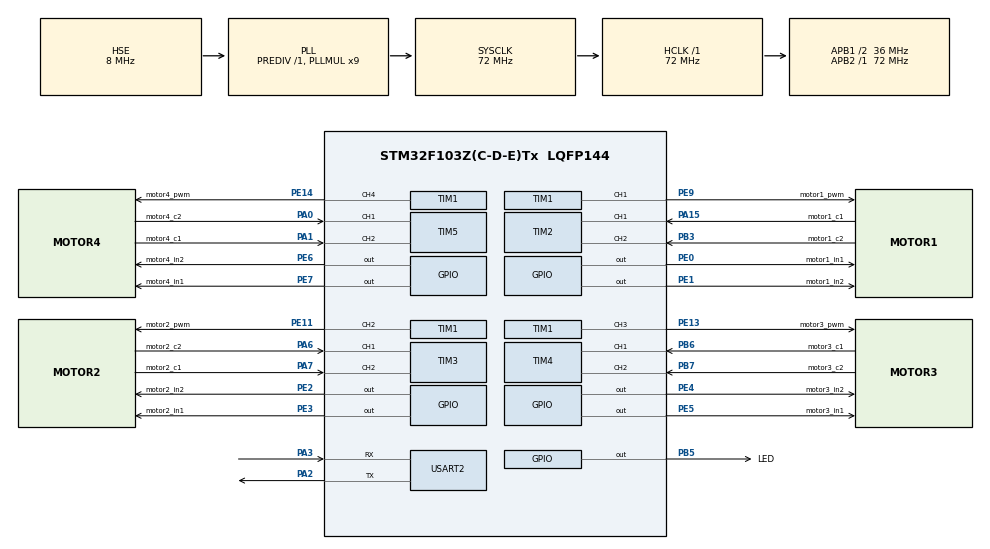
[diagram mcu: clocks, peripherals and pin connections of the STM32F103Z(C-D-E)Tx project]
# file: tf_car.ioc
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Mcu.Family=STM32F1
Mcu.Name=STM32F103Z(C-D-E)Tx
Mcu.Package=LQFP144
NVIC.PriorityGroup=NVIC_PRIORITYGROUP_4
NVIC.TIM2_IRQn=true\:0\:0\:false\:false\:true\:true\:true\:true
NVIC.TIM3_IRQn=true\:0\:0\:false\:false\:true\:true\:true\:true
NVIC.TIM4_IRQn=true\:0\:0\:false\:false\:true\:true\:true\:true
NVIC.TIM5_IRQn=true\:0\:0\:false\:false\:true\:true\:true\:true
NVIC.TIM8_UP_IRQn=true\:0\:0\:false\:false\:true\:true\:true\:true
OSC_IN.Mode=HSE-External-Oscillator
OSC_IN.Signal=RCC_OSC_IN
OSC_OUT.Mode=HSE-External-Oscillator
OSC_OUT.Signal=RCC_OSC_OUT
PA0-WKUP.GPIO_Label=motor4_c2
PA0-WKUP.GPIO_PuPd=GPIO_PULLUP
PA0-WKUP.Signal=S_TIM5_CH1
PA1.GPIO_Label=motor4_c1
PA1.GPIO_PuPd=GPIO_PULLUP
PA1.Signal=S_TIM5_CH2
PA13.Mode=Serial_Wire
PA13.Signal=SYS_JTMS-SWDIO
PA14.Mode=Serial_Wire
PA14.Signal=SYS_JTCK-SWCLK
PA15.GPIO_Label=motor1_c1
PA15.GPIO_PuPd=GPIO_PULLUP
PA15.Signal=S_TIM2_CH1_ETR
PA2.Mode=Asynchronous
PA2.Signal=USART2_TX
PA3.Mode=Asynchronous
PA3.Signal=USART2_RX
PA6.GPIO_Label=motor2_c2
PA6.GPIO_PuPd=GPIO_PULLUP
PA6.Signal=S_TIM3_CH1
PA7.GPIO_Label=motor2_c1
PA7.GPIO_PuPd=GPIO_PULLUP
PA7.Signal=S_TIM3_CH2
PB3.GPIO_Label=motor1_c2
PB3.GPIO_PuPd=GPIO_PULLUP
PB3.Signal=S_TIM2_CH2
PB5.GPIO_Label=LED
PB5.Signal=GPIO_Output
PB6.GPIO_Label=motor3_c1
PB6.GPIO_PuPd=GPIO_PULLUP
PB6.Signal=S_TIM4_CH1
PB7.GPIO_Label=motor3_c2
PB7.GPIO_PuPd=GPIO_PULLUP
PB7.Signal=S_TIM4_CH2
PE0.GPIO_Label=motor1_in1
PE0.Signal=GPIO_Output
PE1.GPIO_Label=motor1_in2
PE1.Signal=GPIO_Output
PE11.GPIO_Label=motor2_pwm
PE11.Signal=S_TIM1_CH2
PE13.GPIO_Label=motor3_pwm
PE13.Signal=S_TIM1_CH3
PE14.GPIO_Label=motor4_pwm
PE14.Signal=S_TIM1_CH4
PE2.GPIO_Label=motor2_in2
PE2.Signal=GPIO_Output
PE3.GPIO_Label=motor2_in1
PE3.Signal=GPIO_Output
PE4.GPIO_Label=motor3_in2
PE4.Signal=GPIO_Output
PE5.GPIO_Label=motor3_in1
PE5.Signal=GPIO_Output
PE6.GPIO_Label=motor4_in2
PE6.Signal=GPIO_Output
PE7.GPIO_Label=motor4_in1
PE7.Signal=GPIO_Output
PE9.GPIO_Label=motor1_pwm
PE9.Signal=S_TIM1_CH1
ProjectManager.HeapSize=0x200
ProjectManager.StackSize=0x400
ProjectManager.TargetToolchain=MDK-ARM V5.32
RCC.AHBFreq_Value=72000000
RCC.APB1CLKDivider=RCC_HCLK_DIV2
RCC.APB1Freq_Value=36000000
RCC.APB1TimFreq_Value=72000000
RCC.APB2Freq_Value=72000000
RCC.APB2TimFreq_Value=72000000
RCC.HCLKFreq_Value=72000000
RCC.PLLMUL=RCC_PLL_MUL9
RCC.PLLSourceVirtual=RCC_PLLSOURCE_HSE
RCC.SYSCLKFreq_VALUE=72000000
RCC.SYSCLKSource=RCC_SYSCLKSOURCE_PLLCLK
RCC.USBFreq_Value=72000000
SH.S_TIM1_CH1.0=TIM1_CH1,PWM Generation1 CH1
SH.S_TIM1_CH2.0=TIM1_CH2,PWM Generation2 CH2
SH.S_TIM1_CH3.0=TIM1_CH3,PWM Generation3 CH3
SH.S_TIM1_CH4.0=TIM1_CH4,PWM Generation4 CH4
SH.S_TIM2_CH1_ETR.0=TIM2_CH1,Encoder_Interface
SH.S_TIM2_CH2.0=TIM2_CH2,Encoder_Interface
SH.S_TIM3_CH1.0=TIM3_CH1,Encoder_Interface
SH.S_TIM3_CH2.0=TIM3_CH2,Encoder_Interface
SH.S_TIM4_CH1.0=TIM4_CH1,Encoder_Interface
SH.S_TIM4_CH2.0=TIM4_CH2,Encoder_Interface
SH.S_TIM5_CH1.0=TIM5_CH1,Encoder_Interface
SH.S_TIM5_CH2.0=TIM5_CH2,Encoder_Interface
TIM1.AutoReloadPreload=TIM_AUTORELOAD_PRELOAD_ENABLE
TIM1.Channel-PWM\ Generation1\ CH1=TIM_CHANNEL_1
TIM1.Channel-PWM\ Generation2\ CH2=TIM_CHANNEL_2
TIM1.Channel-PWM\ Generation3\ CH3=TIM_CHANNEL_3
TIM1.Channel-PWM\ Generation4\ CH4=TIM_CHANNEL_4
TIM1.Period=100-1
TIM1.Prescaler=1440-1
TIM1.Pulse-PWM\ Generation1\ CH1=50
TIM1.Pulse-PWM\ Generation2\ CH2=50
TIM1.Pulse-PWM\ Generation3\ CH3=50
TIM1.Pulse-PWM\ Generation4\ CH4=50
TIM2.EncoderMode=TIM_ENCODERMODE_TI12
TIM2.IC1Filter=6
TIM2.IC2Filter=6
TIM3.EncoderMode=TIM_ENCODERMODE_TI12
TIM3.IC1Filter=6
TIM3.IC2Filter=6
TIM4.EncoderMode=TIM_ENCODERMODE_TI12
TIM4.IC1Filter=6
TIM4.IC2Filter=6
TIM5.EncoderMode=TIM_ENCODERMODE_TI12
TIM5.IC1Filter=6
TIM5.IC2Filter=6
TIM8.AutoReloadPreload=TIM_AUTORELOAD_PRELOAD_ENABLE
TIM8.Period=100-1
TIM8.Prescaler=1440-1
USART2.VirtualMode=VM_ASYNC
VP_TIM8_VS_ClockSourceINT.Mode=Internal
board=custom

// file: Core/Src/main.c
/* USER CODE BEGIN Header */
/**
  ******************************************************************************
  * @file           : main.c
  * @brief          : Main program body
  ******************************************************************************
  * @attention
  *
  * Copyright (c) 2023 STMicroelectronics.
  * All rights reserved.
  *
  * This software is licensed under terms that can be found in the LICENSE file
  * in the root directory of this software component.
  * If no LICENSE file comes with this software, it is provided AS-IS.
  *
  ******************************************************************************
  */
/* USER CODE END Header */
#include "main.h"
#include "tim.h"
#include "usart.h"
#include "gpio.h"

/* USER CODE BEGIN Includes */
#include "stdio.h"
#include "motor.h"
#include "encoder.h"
#include "pid.h"
/* USER CODE END Includes */

void SystemClock_Config(void);

/* USER CODE BEGIN 0 */
extern short encoder1count;
extern short encoder2count;
extern short encoder3count;
extern short encoder4count;
extern tpid pid1,pid2,pid3,pid4;
/* USER CODE END 0 */

int main(void)
{

  /* MCU Configuration--------------------------------------------------------*/

  /* Reset of all peripherals, Initializes the Flash interface and the Systick. */
  HAL_Init();

  /* Configure the system clock */
  SystemClock_Config();

  /* Initialize all configured peripherals */
  MX_GPIO_Init();
  MX_USART2_UART_Init();
  MX_TIM1_Init();
  MX_TIM2_Init();
  MX_TIM3_Init();
  MX_TIM4_Init();
  MX_TIM5_Init();
  MX_TIM8_Init();
  /* USER CODE BEGIN 2 */
	motor_pwm_init();
	motor_encoder_init();
	pid_init();
  /* USER CODE END 2 */

  /* Infinite loop */
  while (1)
  {

    /* USER CODE BEGIN 3 */
//		pid_realize(&pid1,1);
//		pid_realize(&pid2,1);
//		pid_realize(&pid3,1);
//		pid_realize(&pid4,1);
//		motor_pwm_set(pid1.out,pid2.out,pid3.out,pid4.out);
//		HAL_Delay(500);
//		motor_pwm_set(-40,-40,-40,-40);
//		uint8_t c_Data[]="����̫��\r\n";
//		HAL_UART_Transmit(&huart2,c_Data,sizeof(c_Data),0xffff);
		motor_encoder_getdata();
//		printf("1:%d\r\n",encoder1count);
//		printf("2:%d\r\n",encoder2count);
//		printf("3:%d\r\n",encoder3count);
//		printf("4:%d\r\n",encoder4count);
		HAL_Delay(10);
  }
  /* USER CODE END 3 */
}

void SystemClock_Config(void)
{
  RCC_OscInitTypeDef RCC_OscInitStruct = {0};
  RCC_ClkInitTypeDef RCC_ClkInitStruct = {0};

  /** Initializes the RCC Oscillators according to the specified parameters
  * in the RCC_OscInitTypeDef structure.
  */
  RCC_OscInitStruct.OscillatorType = RCC_OSCILLATORTYPE_HSE;
  RCC_OscInitStruct.HSEState = RCC_HSE_ON;
  RCC_OscInitStruct.HSEPredivValue = RCC_HSE_PREDIV_DIV1;
  RCC_OscInitStruct.HSIState = RCC_HSI_ON;
  RCC_OscInitStruct.PLL.PLLState = RCC_PLL_ON;
  RCC_OscInitStruct.PLL.PLLSource = RCC_PLLSOURCE_HSE;
  RCC_OscInitStruct.PLL.PLLMUL = RCC_PLL_MUL9;
  if (HAL_RCC_OscConfig(&RCC_OscInitStruct) != HAL_OK)
  {
    Error_Handler();
  }

  /** Initializes the CPU, AHB and APB buses clocks
  */
  RCC_ClkInitStruct.ClockType = RCC_CLOCKTYPE_HCLK|RCC_CLOCKTYPE_SYSCLK
                              |RCC_CLOCKTYPE_PCLK1|RCC_CLOCKTYPE_PCLK2;
  RCC_ClkInitStruct.SYSCLKSource = RCC_SYSCLKSOURCE_PLLCLK;
  RCC_ClkInitStruct.AHBCLKDivider = RCC_SYSCLK_DIV1;
  RCC_ClkInitStruct.APB1CLKDivider = RCC_HCLK_DIV2;
  RCC_ClkInitStruct.APB2CLKDivider = RCC_HCLK_DIV1;

  if (HAL_RCC_ClockConfig(&RCC_ClkInitStruct, FLASH_LATENCY_2) != HAL_OK)
  {
    Error_Handler();
  }
}

void Error_Handler(void)
{
  __disable_irq();
  while (1)
  {
  }
}
